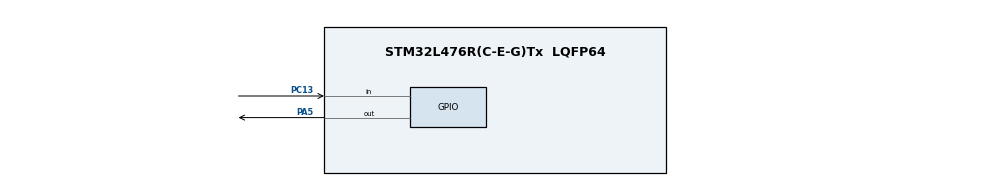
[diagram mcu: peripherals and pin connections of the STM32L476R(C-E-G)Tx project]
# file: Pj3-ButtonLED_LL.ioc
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Mcu.Family=STM32L4
Mcu.Name=STM32L476R(C-E-G)Tx
Mcu.Package=LQFP64
NVIC.PriorityGroup=NVIC_PRIORITYGROUP_4
PA5.Signal=GPIO_Output
PC13.Signal=GPIO_Input
ProjectManager.HeapSize=0x200
ProjectManager.StackSize=0x400
ProjectManager.TargetToolchain=MDK-ARM V5.32
RCC.HSE_VALUE=8000000
RCC.HSI_VALUE=16000000
RCC.LSE_VALUE=32768
RCC.MSI_VALUE=4000000
RCC.VCOOutputFreq_Value=32000000
board=custom

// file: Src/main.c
/* USER CODE BEGIN Header */
/**
  ******************************************************************************
  * @file           : main.c
  * @brief          : Main program body
  ******************************************************************************
  * @attention
  *
  * Copyright (c) 2024 STMicroelectronics.
  * All rights reserved.
  *
  * This software is licensed under terms that can be found in the LICENSE file
  * in the root directory of this software component.
  * If no LICENSE file comes with this software, it is provided AS-IS.
  *
  ******************************************************************************
  */
/* USER CODE END Header */
#include "main.h"

void SystemClock_Config(void);
static void MX_GPIO_Init(void);
/* USER CODE BEGIN PFP */
void delay(__IO uint32_t timedelay);
/* USER CODE END PFP */

int main(void)
{

  /* MCU Configuration--------------------------------------------------------*/

  /* Reset of all peripherals, Initializes the Flash interface and the Systick. */
  //LL_APB2_GRP1_EnableClock(LL_APB2_GRP1_PERIPH_SYSCFG);
  //LL_APB1_GRP1_EnableClock(LL_APB1_GRP1_PERIPH_PWR);

  /* System interrupt init*/
  //NVIC_SetPriorityGrouping(NVIC_PRIORITYGROUP_4);

  /* SysTick_IRQn interrupt configuration */
  //NVIC_SetPriority(SysTick_IRQn, NVIC_EncodePriority(NVIC_GetPriorityGrouping(),15, 0));

  /* Configure the system clock */
  //SystemClock_Config();

  /* Initialize all configured peripherals */
  MX_GPIO_Init();

  /* Infinite loop */
  /* USER CODE BEGIN WHILE */
  // Variable to keep track of the button state
	uint8_t button_pressed = 0;

	while (1)
	{
		// Check if the button is pressed
		if (!LL_GPIO_IsInputPinSet(GPIOC, LL_GPIO_PIN_13))
		{
			// If the button was not previously pressed, it is a new press
			if (button_pressed == 0)
			{
				button_pressed = 1;  // Mark the button as pressed

				// Toggle the LED state
				if (LL_GPIO_IsOutputPinSet(GPIOA, LL_GPIO_PIN_5))
				{
					LL_GPIO_ResetOutputPin(GPIOA, LL_GPIO_PIN_5);
				}
				else
				{
					LL_GPIO_SetOutputPin(GPIOA, LL_GPIO_PIN_5);
				}
			}
		}
		else
		{
			// If the button is not pressed, reset the state
			button_pressed = 0;
		}
		delay(50);  // Small delay for debouncing
	}
}

void SystemClock_Config(void)
{
  LL_FLASH_SetLatency(LL_FLASH_LATENCY_0);
  while(LL_FLASH_GetLatency()!= LL_FLASH_LATENCY_0)
  {
  }
  LL_PWR_SetRegulVoltageScaling(LL_PWR_REGU_VOLTAGE_SCALE1);
  while (LL_PWR_IsActiveFlag_VOS() != 0)
  {
  }
  LL_RCC_MSI_Enable();

   /* Wait till MSI is ready */
  while(LL_RCC_MSI_IsReady() != 1)
  {

  }
  LL_RCC_MSI_EnableRangeSelection();
  LL_RCC_MSI_SetRange(LL_RCC_MSIRANGE_6);
  LL_RCC_MSI_SetCalibTrimming(0);
  LL_RCC_SetSysClkSource(LL_RCC_SYS_CLKSOURCE_MSI);

   /* Wait till System clock is ready */
  while(LL_RCC_GetSysClkSource() != LL_RCC_SYS_CLKSOURCE_STATUS_MSI)
  {

  }
  LL_RCC_SetAHBPrescaler(LL_RCC_SYSCLK_DIV_1);
  LL_RCC_SetAPB1Prescaler(LL_RCC_APB1_DIV_1);
  LL_RCC_SetAPB2Prescaler(LL_RCC_APB2_DIV_1);

  LL_Init1msTick(4000000);

  LL_SetSystemCoreClock(4000000);
}

static void MX_GPIO_Init(void)
{
  LL_GPIO_InitTypeDef GPIO_InitStruct = {0};

  /* GPIO Ports Clock Enable */
  LL_AHB2_GRP1_EnableClock(LL_AHB2_GRP1_PERIPH_GPIOC);
  LL_AHB2_GRP1_EnableClock(LL_AHB2_GRP1_PERIPH_GPIOA);

  /**/
  LL_GPIO_ResetOutputPin(GPIOA, LL_GPIO_PIN_5);

  /**/
  GPIO_InitStruct.Pin = LL_GPIO_PIN_13;
  GPIO_InitStruct.Mode = LL_GPIO_MODE_INPUT;
  GPIO_InitStruct.Pull = LL_GPIO_PULL_UP;
  LL_GPIO_Init(GPIOC, &GPIO_InitStruct);

  /**/
  GPIO_InitStruct.Pin = LL_GPIO_PIN_5;
  GPIO_InitStruct.Mode = LL_GPIO_MODE_OUTPUT;
  GPIO_InitStruct.Speed = LL_GPIO_SPEED_FREQ_LOW;
  GPIO_InitStruct.OutputType = LL_GPIO_OUTPUT_PUSHPULL;
  GPIO_InitStruct.Pull = LL_GPIO_PULL_NO;
  LL_GPIO_Init(GPIOA, &GPIO_InitStruct);

}

/* USER CODE BEGIN 4 */
void delay(__IO uint32_t timedelay)
{
	for(uint32_t i=0; i < timedelay*1000; i++){}
}
/* USER CODE END 4 */

void Error_Handler(void)
{
  __disable_irq();
  while (1)
  {
  }
}
